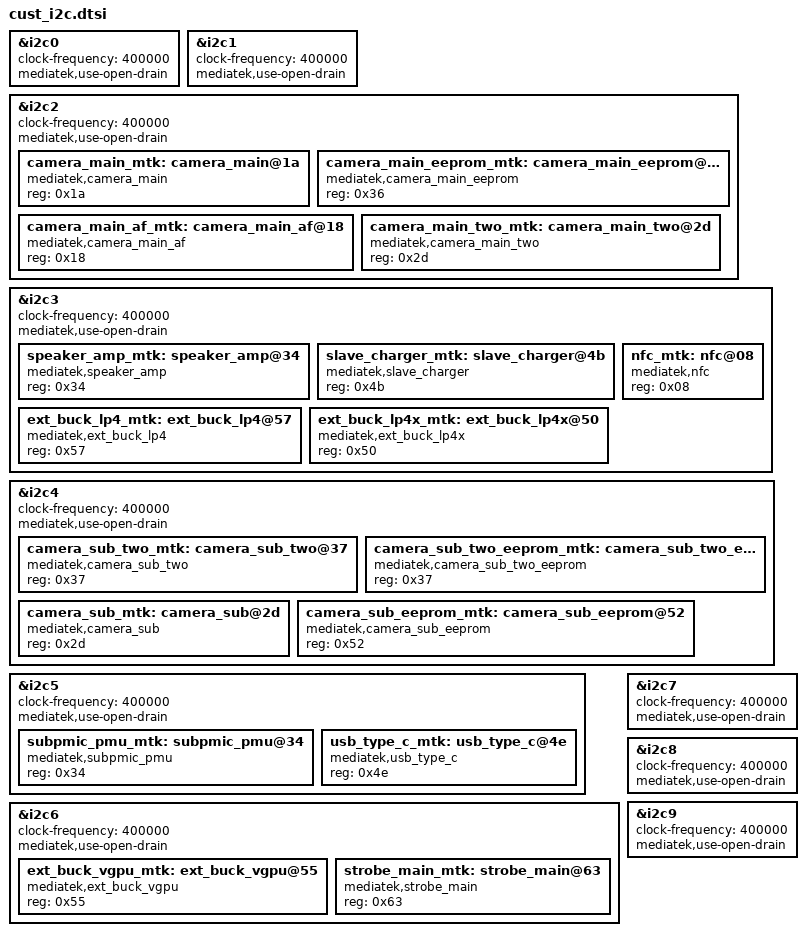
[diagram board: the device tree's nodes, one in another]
/*
 * Generated by MTK SP DrvGen Version: 3.5.160809 for MT6765.
 * 2026-08-02 08:23:43
 * Do Not Modify The File.
 * Copyright Mediatek Inc. (c) 2016.
*/

/*************************
 * I2C DTSI File
*************************/

&i2c0 {
	#address-cells = <1>;
	#size-cells = <0>;
	clock-frequency = <400000>;
	mediatek,use-open-drain;
};

&i2c1 {
	#address-cells = <1>;
	#size-cells = <0>;
	clock-frequency = <400000>;
	mediatek,use-open-drain;
};

&i2c2 {
	#address-cells = <1>;
	#size-cells = <0>;
	clock-frequency = <400000>;
	mediatek,use-open-drain;
	camera_main_mtk:camera_main@1a {
		compatible = "mediatek,camera_main";
		reg = <0x1a>;
		status = "okay";
	};

	camera_main_eeprom_mtk:camera_main_eeprom@36 {
		compatible = "mediatek,camera_main_eeprom";
		reg = <0x36>;
		status = "okay";
	};

	camera_main_af_mtk:camera_main_af@18 {
		compatible = "mediatek,camera_main_af";
		reg = <0x18>;
		status = "okay";
	};

	camera_main_two_mtk:camera_main_two@2d {
		compatible = "mediatek,camera_main_two";
		reg = <0x2d>;
		status = "okay";
	};

};

&i2c3 {
	#address-cells = <1>;
	#size-cells = <0>;
	clock-frequency = <400000>;
	mediatek,use-open-drain;
	speaker_amp_mtk:speaker_amp@34 {
		compatible = "mediatek,speaker_amp";
		reg = <0x34>;
		status = "okay";
	};

	slave_charger_mtk:slave_charger@4b {
		compatible = "mediatek,slave_charger";
		reg = <0x4b>;
		status = "okay";
	};

	nfc_mtk:nfc@08 {
		compatible = "mediatek,nfc";
		reg = <0x08>;
		status = "okay";
	};

	ext_buck_lp4_mtk:ext_buck_lp4@57 {
		compatible = "mediatek,ext_buck_lp4";
		reg = <0x57>;
		status = "okay";
	};

	ext_buck_lp4x_mtk:ext_buck_lp4x@50 {
		compatible = "mediatek,ext_buck_lp4x";
		reg = <0x50>;
		status = "okay";
	};

};

&i2c4 {
	#address-cells = <1>;
	#size-cells = <0>;
	clock-frequency = <400000>;
	mediatek,use-open-drain;
	camera_sub_two_mtk:camera_sub_two@37 {
		compatible = "mediatek,camera_sub_two";
		reg = <0x37>;
		status = "okay";
	};

	camera_sub_two_eeprom_mtk:camera_sub_two_eeprom@37 {
		compatible = "mediatek,camera_sub_two_eeprom";
		reg = <0x37>;
		status = "okay";
	};

	camera_sub_mtk:camera_sub@2d {
		compatible = "mediatek,camera_sub";
		reg = <0x2d>;
		status = "okay";
	};

	camera_sub_eeprom_mtk:camera_sub_eeprom@52 {
		compatible = "mediatek,camera_sub_eeprom";
		reg = <0x52>;
		status = "okay";
	};

};

&i2c5 {
	#address-cells = <1>;
	#size-cells = <0>;
	clock-frequency = <400000>;
	mediatek,use-open-drain;
	subpmic_pmu_mtk:subpmic_pmu@34 {
		compatible = "mediatek,subpmic_pmu";
		reg = <0x34>;
		status = "okay";
	};

	usb_type_c_mtk:usb_type_c@4e {
		compatible = "mediatek,usb_type_c";
		reg = <0x4e>;
		status = "okay";
	};

};

&i2c6 {
	#address-cells = <1>;
	#size-cells = <0>;
	clock-frequency = <400000>;
	mediatek,use-open-drain;
	ext_buck_vgpu_mtk:ext_buck_vgpu@55 {
		compatible = "mediatek,ext_buck_vgpu";
		reg = <0x55>;
		status = "okay";
	};

	strobe_main_mtk:strobe_main@63 {
		compatible = "mediatek,strobe_main";
		reg = <0x63>;
		status = "okay";
	};

};

&i2c7 {
	#address-cells = <1>;
	#size-cells = <0>;
	clock-frequency = <400000>;
	mediatek,use-open-drain;
};

&i2c8 {
	#address-cells = <1>;
	#size-cells = <0>;
	clock-frequency = <400000>;
	mediatek,use-open-drain;
};

&i2c9 {
	#address-cells = <1>;
	#size-cells = <0>;
	clock-frequency = <400000>;
	mediatek,use-open-drain;
};

